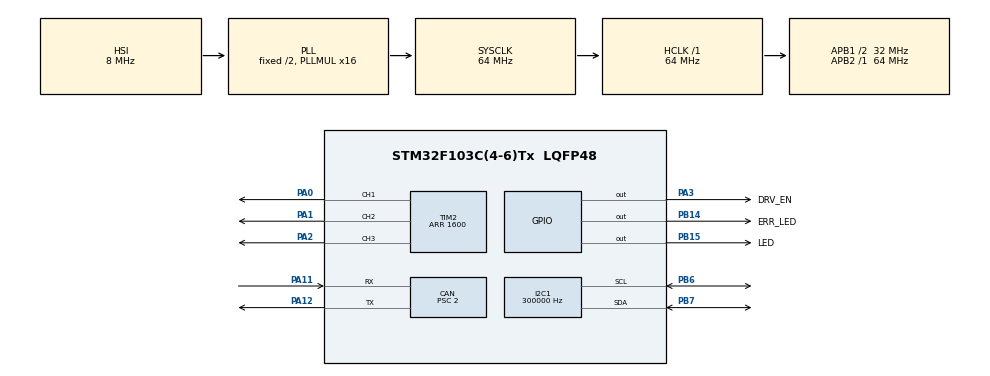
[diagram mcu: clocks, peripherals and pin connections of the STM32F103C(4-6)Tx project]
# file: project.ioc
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CAN.ABOM=ENABLE
CAN.AWUM=ENABLE
CAN.BS1=CAN_BS1_11TQ
CAN.BS2=CAN_BS2_4TQ
CAN.CalculateBaudRate=1000000
CAN.CalculateTimeBit=1000
CAN.CalculateTimeQuantum=62.5
CAN.NART=ENABLE
CAN.Prescaler=2
Dma.I2C1_RX.0.Direction=DMA_PERIPH_TO_MEMORY
Dma.I2C1_RX.0.Instance=DMA1_Channel7
Dma.I2C1_RX.0.MemDataAlignment=DMA_MDATAALIGN_BYTE
Dma.I2C1_RX.0.MemInc=DMA_MINC_ENABLE
Dma.I2C1_RX.0.Mode=DMA_NORMAL
Dma.I2C1_RX.0.PeriphDataAlignment=DMA_PDATAALIGN_BYTE
Dma.I2C1_RX.0.PeriphInc=DMA_PINC_DISABLE
Dma.I2C1_RX.0.Priority=DMA_PRIORITY_LOW
Dma.Request0=I2C1_RX
I2C1.ClockSpeed=300000
I2C1.DutyCycle=I2C_DUTYCYCLE_16_9
I2C1.I2C_Mode=I2C_Fast
Mcu.Family=STM32F1
Mcu.Name=STM32F103C(4-6)Tx
Mcu.Package=LQFP48
NVIC.DMA1_Channel7_IRQn=true\:1\:0\:true\:false\:true\:false\:true\:true
NVIC.PriorityGroup=NVIC_PRIORITYGROUP_4
NVIC.TIM2_IRQn=true\:0\:0\:false\:false\:true\:true\:true\:true
NVIC.USB_LP_CAN1_RX0_IRQn=true\:2\:0\:true\:false\:true\:true\:true\:true
PA0-WKUP.GPIO_Speed=GPIO_SPEED_FREQ_LOW
PA0-WKUP.Signal=S_TIM2_CH1_ETR
PA1.GPIO_Speed=GPIO_SPEED_FREQ_LOW
PA1.Signal=S_TIM2_CH2
PA11.Mode=CAN_Activate
PA11.Signal=CAN_RX
PA12.Mode=CAN_Activate
PA12.Signal=CAN_TX
PA13.Mode=Serial_Wire
PA13.Signal=SYS_JTMS-SWDIO
PA14.Mode=Serial_Wire
PA14.Signal=SYS_JTCK-SWCLK
PA2.GPIO_Speed=GPIO_SPEED_FREQ_LOW
PA2.Signal=S_TIM2_CH3
PA3.GPIO_Label=DRV_EN
PA3.Signal=GPIO_Output
PB14.GPIO_Label=ERR_LED
PB14.Signal=GPIO_Output
PB15.GPIO_Label=LED
PB15.Signal=GPIO_Output
PB6.Mode=I2C
PB6.Signal=I2C1_SCL
PB7.Mode=I2C
PB7.Signal=I2C1_SDA
PD0-OSC_IN.Mode=HSE-External-Oscillator
PD0-OSC_IN.Signal=RCC_OSC_IN
PD1-OSC_OUT.Mode=HSE-External-Oscillator
PD1-OSC_OUT.Signal=RCC_OSC_OUT
ProjectManager.HeapSize=0x200
ProjectManager.StackSize=0x400
ProjectManager.TargetToolchain=CMake
RCC.AHBFreq_Value=64000000
RCC.APB1CLKDivider=RCC_HCLK_DIV2
RCC.APB1Freq_Value=32000000
RCC.APB1TimFreq_Value=64000000
RCC.APB2Freq_Value=64000000
RCC.APB2TimFreq_Value=64000000
RCC.HCLKFreq_Value=64000000
RCC.PLLMUL=RCC_PLL_MUL16
RCC.SYSCLKFreq_VALUE=64000000
RCC.SYSCLKSource=RCC_SYSCLKSOURCE_PLLCLK
RCC.USBFreq_Value=64000000
SH.S_TIM2_CH1_ETR.0=TIM2_CH1,PWM Generation1 CH1
SH.S_TIM2_CH2.0=TIM2_CH2,PWM Generation2 CH2
SH.S_TIM2_CH3.0=TIM2_CH3,PWM Generation3 CH3
TIM1.Period=65535
TIM1.Prescaler=64-1
TIM2.AutoReloadPreload=TIM_AUTORELOAD_PRELOAD_ENABLE
TIM2.Channel-Output\ Compare4\ No\ Output=TIM_CHANNEL_4
TIM2.Channel-PWM\ Generation1\ CH1=TIM_CHANNEL_1
TIM2.Channel-PWM\ Generation2\ CH2=TIM_CHANNEL_2
TIM2.Channel-PWM\ Generation3\ CH3=TIM_CHANNEL_3
TIM2.CounterMode=TIM_COUNTERMODE_CENTERALIGNED1
TIM2.OCFastMode_PWM-PWM\ Generation1\ CH1=TIM_OCFAST_DISABLE
TIM2.Period=1600
TIM2.Pulse-Output\ Compare4\ No\ Output=800
TIM2.TIM_MasterOutputTrigger=TIM_TRGO_RESET
TIM2.TIM_MasterSlaveMode=TIM_MASTERSLAVEMODE_DISABLE
VP_TIM1_VS_ClockSourceINT.Mode=Internal
VP_TIM2_VS_ClockSourceINT.Mode=Internal
VP_TIM2_VS_no_output4.Mode=Output Compare4 No Output
board=custom

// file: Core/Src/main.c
/* USER CODE BEGIN Header */
/**
  ******************************************************************************
  * @file           : main.c
  * @brief          : Main program body
  ******************************************************************************
  * @attention
  *
  * Copyright (c) 2026 STMicroelectronics.
  * All rights reserved.
  *
  * This software is licensed under terms that can be found in the LICENSE file
  * in the root directory of this software component.
  * If no LICENSE file comes with this software, it is provided AS-IS.
  *
  ******************************************************************************
  */
/* USER CODE END Header */
#include "main.h"
#include "can.h"
#include "dma.h"
#include "i2c.h"
#include "tim.h"
#include "gpio.h"

/* USER CODE BEGIN Includes */
extern void app_init(void);
extern void app_loop(void);
/* USER CODE END Includes */

void SystemClock_Config(void);

int main(void)
{

  /* USER CODE BEGIN 1 */
  SCB->VTOR = 0x08002000U;
  __DSB();
  __ISB();
  /* A bootloader jump preserves PRIMASK; a hardware reset already has it clear. */
  __enable_irq();
  /* USER CODE END 1 */

  /* MCU Configuration--------------------------------------------------------*/

  /* Reset of all peripherals, Initializes the Flash interface and the Systick. */
  HAL_Init();

  /* Configure the system clock */
  SystemClock_Config();

  /* Initialize all configured peripherals */
  MX_GPIO_Init();
  MX_DMA_Init();
  MX_CAN_Init();
  MX_I2C1_Init();
  MX_TIM2_Init();
  MX_TIM1_Init();
  /* USER CODE BEGIN 2 */
  app_init();
  /* USER CODE END 2 */

  /* Infinite loop */
  /* USER CODE BEGIN WHILE */
  while (1)
  {
    app_loop();
    /* USER CODE END WHILE */

  }
}

void SystemClock_Config(void)
{
  RCC_OscInitTypeDef RCC_OscInitStruct = {0};
  RCC_ClkInitTypeDef RCC_ClkInitStruct = {0};

  /** Initializes the RCC Oscillators according to the specified parameters
  * in the RCC_OscInitTypeDef structure.
  */
  RCC_OscInitStruct.OscillatorType = RCC_OSCILLATORTYPE_HSI;
  RCC_OscInitStruct.HSIState = RCC_HSI_ON;
  RCC_OscInitStruct.HSICalibrationValue = RCC_HSICALIBRATION_DEFAULT;
  RCC_OscInitStruct.PLL.PLLState = RCC_PLL_ON;
  RCC_OscInitStruct.PLL.PLLSource = RCC_PLLSOURCE_HSI_DIV2;
  RCC_OscInitStruct.PLL.PLLMUL = RCC_PLL_MUL16;
  if (HAL_RCC_OscConfig(&RCC_OscInitStruct) != HAL_OK)
  {
    Error_Handler();
  }

  /** Initializes the CPU, AHB and APB buses clocks
  */
  RCC_ClkInitStruct.ClockType = RCC_CLOCKTYPE_HCLK|RCC_CLOCKTYPE_SYSCLK
                              |RCC_CLOCKTYPE_PCLK1|RCC_CLOCKTYPE_PCLK2;
  RCC_ClkInitStruct.SYSCLKSource = RCC_SYSCLKSOURCE_PLLCLK;
  RCC_ClkInitStruct.AHBCLKDivider = RCC_SYSCLK_DIV1;
  RCC_ClkInitStruct.APB1CLKDivider = RCC_HCLK_DIV2;
  RCC_ClkInitStruct.APB2CLKDivider = RCC_HCLK_DIV1;

  if (HAL_RCC_ClockConfig(&RCC_ClkInitStruct, FLASH_LATENCY_2) != HAL_OK)
  {
    Error_Handler();
  }
}

void Error_Handler(void)
{
  __disable_irq();
  while (1)
  {
  }
}
